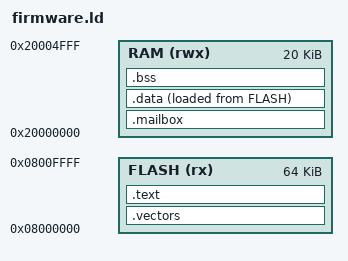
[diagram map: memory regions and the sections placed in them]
/* Copyright (c) 2026 Ricardo Kerschbaumer; SPDX-License-Identifier: MIT */
ENTRY(Reset_Handler)
MEMORY {
    FLASH (rx) : ORIGIN = 0x08000000, LENGTH = 64K
    RAM (rwx) : ORIGIN = 0x20000000, LENGTH = 20K
}
_stack_top = ORIGIN(RAM) + LENGTH(RAM);
SECTIONS {
    .vectors : { KEEP(*(.vectors)) } > FLASH
    .text : { *(.text*) *(.rodata*) } > FLASH
    .mailbox (NOLOAD) : { KEEP(*(.mailbox)) . = ORIGIN(RAM) + 0x100; } > RAM
    .data : {
        _data_start = .;
        *(.data*)
        . = ALIGN(4);
        _data_end = .;
    } > RAM AT> FLASH
    _data_load = LOADADDR(.data);
    .bss (NOLOAD) : {
        _bss_start = .;
        *(.bss*) *(COMMON)
        . = ALIGN(4);
        _bss_end = .;
    } > RAM
    /DISCARD/ : { *(.comment) *(.ARM.exidx*) *(.ARM.extab*) *(.eh_frame*) }
}
ASSERT(_bss_end <= _stack_top - 1024, "Keep at least 1 KiB for the stack")
